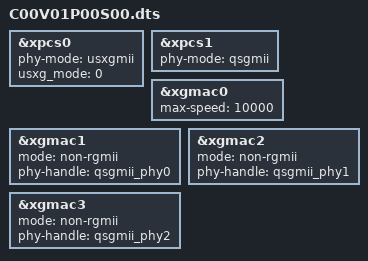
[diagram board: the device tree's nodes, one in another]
/*C00.V01.P00.S00*/
//serde0 10G sfp
//serdes1 QSGMII
//RGMII1
/dts-v1/;
/plugin/;
/ {
	fragment@0 {
		target=<&xpcs0>;
		__overlay__ {
			phy-mode = "usxgmii";
			usxg_mode = <0>;
			status = "okay";
		};
	};

	fragment@1 {
		target=<&xpcs1>;
		__overlay__ {
			phy-mode = "qsgmii";
			status = "okay";
		};
	};

	fragment@2 {
		target=<&xgmac0>;
		__overlay__ {
			max-speed = <10000>;
		};
	};

	fragment@3  {
		target=<&xgmac1>;
		__overlay__ {
			mode = "non-rgmii";
			phy-handle = <&qsgmii_phy0>;
			status = "okay";
		};
	};

	fragment@4 {
		target = <&xgmac2>;
		__overlay__ {
			mode = "non-rgmii";
			phy-handle = <&qsgmii_phy1>;
			status = "okay";
		};
	};

	fragment@5 {
		target = <&xgmac3>;
		__overlay__ {
			mode = "non-rgmii";
			phy-handle = <&qsgmii_phy2>;
			status = "okay";
		};
	};
};
